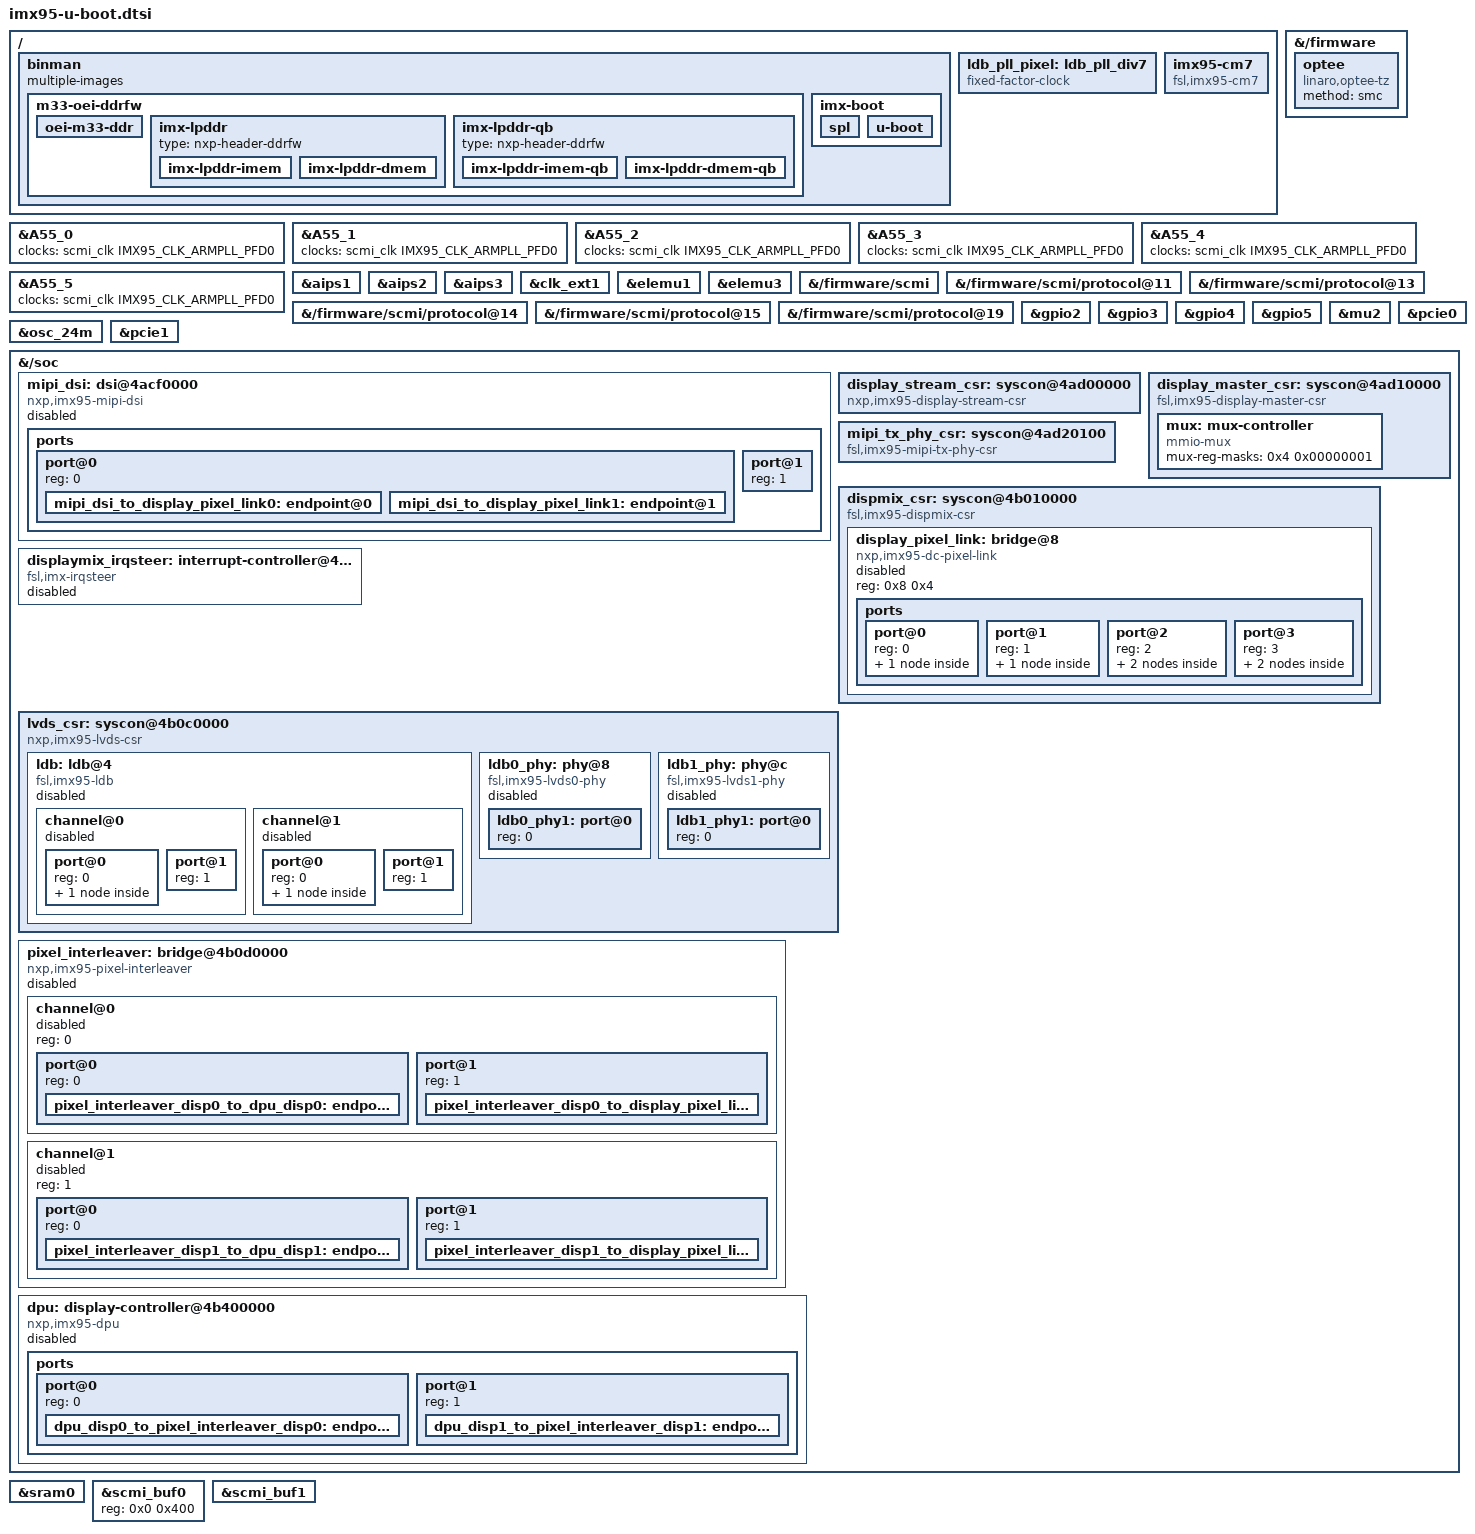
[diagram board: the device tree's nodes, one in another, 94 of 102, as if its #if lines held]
// SPDX-License-Identifier: GPL-2.0+
/*
 * Copyright 2025 NXP
 */

 #include <dt-bindings/clock/nxp,imx95-clock.h>

#ifdef CONFIG_OPTEE
&{/firmware} {
	optee {
		compatible = "linaro,optee-tz";
		method = "smc";
	};
};
#endif

/ {
	binman {
		multiple-images;

		m33-oei-ddrfw {
			pad-byte = <0x00>;
			align-size = <0x8>;
			filename = "m33-oei-ddrfw.bin";

			oei-m33-ddr {
				align-size = <0x4>;
				filename = "oei-m33-ddr.bin";
				type = "blob-ext";
			};

			imx-lpddr {
				type = "nxp-header-ddrfw";

				imx-lpddr-imem {
					filename = "lpddr5_imem_v202409.bin";
					type = "blob-ext";
				};

				imx-lpddr-dmem {
					filename = "lpddr5_dmem_v202409.bin";
					type = "blob-ext";
				};
			};

			imx-lpddr-qb {
				type = "nxp-header-ddrfw";

				imx-lpddr-imem-qb {
					filename = "lpddr5_imem_qb_v202409.bin";
					type = "blob-ext";
				};

				imx-lpddr-dmem-qb {
					filename = "lpddr5_dmem_qb_v202409.bin";
					type = "blob-ext";
				};
			};
		};

		imx-boot {
			filename = "flash.bin";
			pad-byte = <0x00>;

			spl {
				type = "nxp-imx9image";
				cfg-path = "spl/u-boot-spl.cfgout";
				args;

#ifndef CONFIG_IMX95_A0
				cntr-version = <2>;
#endif
				boot-from = "sd";
				soc-type = "IMX9";
#ifdef CONFIG_IMX95_A0
				append = "mx95a0-ahab-container.img";
#else
				append = "mx95b0-ahab-container.img";
#endif
				container;
#ifndef CONFIG_IMX95_A0
				dummy-ddr;
#endif
				image0 = "oei", "m33-oei-ddrfw.bin", "0x1ffc0000";
				hold = <0x10000>;
#ifdef CONFIG_IMX95_A0
				image1 = "oei", "oei-m33-tcm.bin", "0x1ffc0000";
#endif
				image2 = "m33", "m33_image.bin", "0x1ffc0000";
				image3 = "a55", "spl/u-boot-spl.bin", "0x20480000";
				dummy-v2x = <0x8b000000>;
			};

			u-boot {
				type = "nxp-imx9image";
				cfg-path = "u-boot-container.cfgout";
				args;

#ifndef CONFIG_IMX95_A0
				cntr-version = <2>;
#endif
				boot-from = "sd";
				soc-type = "IMX9";
				container;
				image0 = "a55", "bl31.bin", "0x8a200000";
				image1 = "a55", "u-boot.bin", "0x90200000";
			};
		};
	};

	ldb_pll_pixel: ldb_pll_div7 {
		#clock-cells = <0>;
		compatible = "fixed-factor-clock";
		clocks = <&scmi_clk IMX95_CLK_LDBPLL>;
		clock-div = <7>;
		clock-mult = <1>;
		clock-output-names = "ldb_pll_div7";
	};

	imx95-cm7 {
		compatible = "fsl,imx95-cm7";
	};
};

&A55_0 {
	clocks = <&scmi_clk IMX95_CLK_ARMPLL_PFD0>;
	/delete-property/ power-domains;
};

&A55_1 {
	clocks = <&scmi_clk IMX95_CLK_ARMPLL_PFD0>;
	/delete-property/ power-domains;
};

&A55_2 {
	clocks = <&scmi_clk IMX95_CLK_ARMPLL_PFD0>;
	/delete-property/ power-domains;
};

&A55_3 {
	clocks = <&scmi_clk IMX95_CLK_ARMPLL_PFD0>;
	/delete-property/ power-domains;
};

&A55_4 {
	clocks = <&scmi_clk IMX95_CLK_ARMPLL_PFD0>;
	/delete-property/ power-domains;
};

&A55_5 {
	clocks = <&scmi_clk IMX95_CLK_ARMPLL_PFD0>;
	/delete-property/ power-domains;
};

&aips1 {
	bootph-all;
};

&aips2 {
	bootph-all;
};

&aips3 {
	bootph-pre-ram;
};

&clk_ext1 {
	bootph-all;
};

&elemu1 {
	bootph-all;
	status = "okay";
};

&elemu3 {
	bootph-all;
	status = "okay";
};

&{/firmware} {
	bootph-all;
};

&{/firmware/scmi} {
	bootph-all;
};

&{/firmware/scmi/protocol@11} {
	bootph-all;
};

&{/firmware/scmi/protocol@13} {
	bootph-all;
};

&{/firmware/scmi/protocol@14} {
	bootph-all;
};

&{/firmware/scmi/protocol@15} {
	bootph-all;
};

&{/firmware/scmi/protocol@19} {
	bootph-all;
};

&gpio2 {
	bootph-pre-ram;
};

&gpio3 {
	bootph-pre-ram;
};

&gpio4 {
	bootph-pre-ram;
};

&gpio5 {
	bootph-pre-ram;
};

&mu2 {
	bootph-all;
};

&osc_24m {
	bootph-all;
};

&pcie0 {
	assigned-clocks =<&scmi_clk IMX95_CLK_HSIOPLL_VCO>,
					 <&scmi_clk IMX95_CLK_HSIOPLL>,
					 <&scmi_clk IMX95_CLK_HSIOPCIEAUX>;
	assigned-clock-parents = <0>, <&scmi_clk IMX95_CLK_HSIOPLL_VCO>,
				 <&scmi_clk IMX95_CLK_SYSPLL1_PFD1_DIV2>;
};

&pcie1 {
	assigned-clocks =<&scmi_clk IMX95_CLK_HSIOPLL_VCO>,
					 <&scmi_clk IMX95_CLK_HSIOPLL>,
					 <&scmi_clk IMX95_CLK_HSIOPCIEAUX>;
	assigned-clock-parents = <0>, <&scmi_clk IMX95_CLK_HSIOPLL_VCO>,
				 <&scmi_clk IMX95_CLK_SYSPLL1_PFD1_DIV2>;
};

&{/soc} {
	bootph-all;

	mipi_dsi: dsi@4acf0000 {
		compatible = "nxp,imx95-mipi-dsi";
		reg = <0x0 0x4acf0000 0x0 0x10000>;
		interrupt-parent = <&displaymix_irqsteer>;
		interrupts = <48>;
		clocks = <&scmi_clk IMX95_CLK_MIPIPHYCFG>,
			 <&scmi_clk IMX95_CLK_MIPIPHYPLLBYPASS>,
			 <&osc_24m>,
			 <&scmi_clk IMX95_CLK_CAMAPB>,
			 <&scmi_clk IMX95_CLK_DISP1PIX>;
		clock-names = "cfg", "bypass", "ref", "pclk", "pix";
		assigned-clocks = <&scmi_clk IMX95_CLK_MIPIPHYCFG>,
				  <&scmi_clk IMX95_CLK_MIPIPHYPLLBYPASS>;
		assigned-clock-parents = <&osc_24m>,
					 <&scmi_clk IMX95_CLK_VIDEOPLL1>;
		mux-controls = <&mux 0>;
		power-domains = <&scmi_devpd IMX95_PD_CAMERA>;
		nxp,disp-master-csr = <&display_master_csr>;
		nxp,disp-stream-csr = <&display_stream_csr>;
		nxp,mipi-combo-phy-csr = <&mipi_tx_phy_csr>;
		status = "disabled";

		ports {
			#address-cells = <1>;
			#size-cells = <0>;

			port@0 {
				#address-cells = <1>;
				#size-cells = <0>;
				reg = <0>;

				mipi_dsi_to_display_pixel_link0: endpoint@0 {
					reg = <0>;
					remote-endpoint = <&display_pixel_link0_to_mipi_dsi>;
				};

				mipi_dsi_to_display_pixel_link1: endpoint@1 {
					reg = <1>;
					remote-endpoint = <&display_pixel_link1_to_mipi_dsi>;
				};
			};

			port@1 {
				reg = <1>;
			};
		};
	};

	display_stream_csr: syscon@4ad00000 {
		compatible = "nxp,imx95-display-stream-csr", "syscon", "simple-mfd";
		reg = <0x0 0x4ad00000 0x0 0x10000>;
		clocks = <&scmi_clk IMX95_CLK_CAMAPB>;
	};

	display_master_csr: syscon@4ad10000 {
		compatible = "fsl,imx95-display-master-csr", "syscon";
		reg = <0x0 0x4ad10000 0x0 0x10000>;
		#clock-cells = <1>;
		clocks = <&scmi_clk IMX95_CLK_CAMAPB>;
		power-domains = <&scmi_devpd IMX95_PD_CAMERA>;

		mux: mux-controller {
			compatible = "mmio-mux";
			#mux-control-cells = <1>;
			mux-reg-masks = <0x4 0x00000001>; /* Pixel_link_sel */
		};
	};

	mipi_tx_phy_csr: syscon@4ad20100 {
		compatible = "fsl,imx95-mipi-tx-phy-csr", "syscon";
		reg = <0x0 0x4ad20100 0x0 0x14>;
		clocks = <&scmi_clk IMX95_CLK_CAMAPB>;
	};

	dispmix_csr: syscon@4b010000 {
		compatible = "fsl,imx95-dispmix-csr", "syscon";
		#address-cells = <1>;
		#size-cells = <1>;
		reg = <0x0 0x4b010000 0x0 0x10000>;
		#clock-cells = <1>;
		clocks = <&scmi_clk IMX95_CLK_DISPAPB>;
		power-domains = <&scmi_devpd IMX95_PD_DISPLAY>;
		assigned-clocks = <&scmi_clk IMX95_CLK_DISPAXI>,
				  <&scmi_clk IMX95_CLK_DISPOCRAM>,
				  <&scmi_clk IMX95_CLK_DISPAPB>;
		assigned-clock-parents = <&scmi_clk IMX95_CLK_SYSPLL1_PFD1>,
					 <&scmi_clk IMX95_CLK_SYSPLL1_PFD1>,
					 <&scmi_clk IMX95_CLK_SYSPLL1_PFD1_DIV2>;
		assigned-clock-rates = <400000000>, <400000000>, <133333333>;

		display_pixel_link: bridge@8 {
			compatible = "nxp,imx95-dc-pixel-link";
			reg = <0x8 0x4>;
			status = "disabled";

			ports {
				#address-cells = <1>;
				#size-cells = <0>;

				port@0 {
					reg = <0>;

					display_pixel_link0_to_pixel_interleaver_disp0: endpoint {
						remote-endpoint = <&pixel_interleaver_disp0_to_display_pixel_link0>;
					};
				};

				port@1 {
					reg = <1>;

					display_pixel_link1_to_pixel_interleaver_disp1: endpoint {
						remote-endpoint = <&pixel_interleaver_disp1_to_display_pixel_link1>;
					};
				};

				port@2 {
					#address-cells = <1>;
					#size-cells = <0>;
					reg = <2>;

					display_pixel_link0_to_mipi_dsi: endpoint@0 {
						reg = <0>;
						remote-endpoint = <&mipi_dsi_to_display_pixel_link0>;
					};

					display_pixel_link0_to_ldb_ch0: endpoint@1 {
						reg = <1>;
						remote-endpoint = <&ldb_ch0_to_display_pixel_link0>;
					};
				};

				port@3 {
					#address-cells = <1>;
					#size-cells = <0>;
					reg = <3>;

					display_pixel_link1_to_mipi_dsi: endpoint@0 {
						reg = <0>;
						remote-endpoint = <&mipi_dsi_to_display_pixel_link1>;
					};

					display_pixel_link1_to_ldb_ch1: endpoint@1 {
						reg = <1>;
						remote-endpoint = <&ldb_ch1_to_display_pixel_link1>;
					};
				};
			};
		};
	};

	displaymix_irqsteer: interrupt-controller@4b0b0000 {
		compatible = "fsl,imx-irqsteer";
		reg = <0x0 0x4b0b0000 0x0 0x1000>;
		interrupts = <GIC_SPI 214 IRQ_TYPE_LEVEL_HIGH>,
			     <GIC_SPI 215 IRQ_TYPE_LEVEL_HIGH>,
			     <GIC_SPI 216 IRQ_TYPE_LEVEL_HIGH>,
			     <GIC_SPI 217 IRQ_TYPE_LEVEL_HIGH>,
			     <GIC_SPI 218 IRQ_TYPE_LEVEL_HIGH>,
			     <GIC_SPI 303 IRQ_TYPE_LEVEL_HIGH>,	/* reserved */
			     <GIC_SPI 303 IRQ_TYPE_LEVEL_HIGH>,	/* reserved */
			     <GIC_SPI 219 IRQ_TYPE_LEVEL_HIGH>;
		power-domains = <&scmi_devpd IMX95_PD_DISPLAY>;
		clocks = <&scmi_clk IMX95_CLK_DISPAPB>;
		clock-names = "ipg";
		fsl,channel = <0>;
		fsl,num-irqs = <512>;
		interrupt-controller;
		#interrupt-cells = <1>;
		status = "disabled";
	};

	lvds_csr: syscon@4b0c0000 {
		compatible = "nxp,imx95-lvds-csr", "syscon";
		#address-cells = <1>;
		#size-cells = <1>;
		reg = <0x0 0x4b0c0000 0x0 0x10000>;
		#clock-cells = <1>;
		clocks = <&scmi_clk IMX95_CLK_DISPAPB>;
		power-domains = <&scmi_devpd IMX95_PD_DISPLAY>;

		ldb: ldb@4 {
			compatible = "fsl,imx95-ldb";
			#address-cells = <1>;
			#size-cells = <0>;
			reg = <0x4 0x4>;
			clocks = <&lvds_csr IMX95_CLK_DISPMIX_PIX_DI0_GATE>,
				 <&lvds_csr IMX95_CLK_DISPMIX_PIX_DI1_GATE>,
				 <&lvds_csr IMX95_CLK_DISPMIX_LVDS_CH0_GATE>,
				 <&lvds_csr IMX95_CLK_DISPMIX_LVDS_CH1_GATE>;
			clock-names = "ldb_di0", "ldb_di1", "ldb_ch0", "ldb_ch1";
			status = "disabled";

			channel@0 {
				#address-cells = <1>;
				#size-cells = <0>;
				reg = <0>;
				phys = <&ldb0_phy1>;
				phy-names = "lvds_phy";
				status = "disabled";

				port@0 {
					reg = <0>;

					ldb_ch0_to_display_pixel_link0: endpoint {
						remote-endpoint = <&display_pixel_link0_to_ldb_ch0>;
					};
				};

				port@1 {
					reg = <1>;
				};
			};

			channel@1 {
				#address-cells = <1>;
				#size-cells = <0>;
				reg = <1>;
				phys = <&ldb1_phy1>;
				phy-names = "lvds_phy";
				status = "disabled";

				port@0 {
					reg = <0>;

					ldb_ch1_to_display_pixel_link1: endpoint {
						remote-endpoint = <&display_pixel_link1_to_ldb_ch1>;
					};
				};

				port@1 {
					reg = <1>;
				};
			};
		};

		ldb0_phy: phy@8 {
			compatible = "fsl,imx95-lvds0-phy";
			#address-cells = <1>;
			#size-cells = <0>;
			reg = <0x8 0x4>;
			gpr = <&lvds_csr>;
			clocks = <&scmi_clk IMX95_CLK_DISPAPB>;
			clock-names = "apb";
			power-domains = <&scmi_devpd IMX95_PD_DISPLAY>;
			status = "disabled";

			ldb0_phy1: port@0 {
				reg = <0>;
				#phy-cells = <0>;
			};
		};

		ldb1_phy: phy@c {
			compatible = "fsl,imx95-lvds1-phy";
			#address-cells = <1>;
			#size-cells = <0>;
			reg = <0xc 0x4>;
			gpr = <&lvds_csr>;
			clocks = <&scmi_clk IMX95_CLK_DISPAPB>;
			clock-names = "apb";
			power-domains = <&scmi_devpd IMX95_PD_DISPLAY>;
			status = "disabled";

			ldb1_phy1: port@0 {
				reg = <0>;
				#phy-cells = <0>;
			};
		};
	};

	pixel_interleaver: bridge@4b0d0000 {
		compatible = "nxp,imx95-pixel-interleaver";
		#address-cells = <1>;
		#size-cells = <0>;
		reg = <0x0 0x4b0d0000 0x0 0x20000>;
		interrupt-parent = <&displaymix_irqsteer>;
		interrupts = <62>;
		clocks = <&scmi_clk IMX95_CLK_DISPAPB>;
		nxp,blk-ctrl = <&dispmix_csr>;
		status = "disabled";

		channel@0 {
			#address-cells = <1>;
			#size-cells = <0>;
			reg = <0>;
			status = "disabled";

			port@0 {
				reg = <0>;

				pixel_interleaver_disp0_to_dpu_disp0: endpoint {
					remote-endpoint = <&dpu_disp0_to_pixel_interleaver_disp0>;
				};
			};

			port@1 {
				reg = <1>;

				pixel_interleaver_disp0_to_display_pixel_link0: endpoint {
					remote-endpoint = <&display_pixel_link0_to_pixel_interleaver_disp0>;
				};
			};
		};

		channel@1 {
			#address-cells = <1>;
			#size-cells = <0>;
			reg = <1>;
			status = "disabled";

			port@0 {
				reg = <0>;

				pixel_interleaver_disp1_to_dpu_disp1: endpoint {
					remote-endpoint = <&dpu_disp1_to_pixel_interleaver_disp1>;
				};
			};

			port@1 {
				reg = <1>;

				pixel_interleaver_disp1_to_display_pixel_link1: endpoint {
					remote-endpoint = <&display_pixel_link1_to_pixel_interleaver_disp1>;
				};
			};
		};
	};

	dpu: display-controller@4b400000 {
		compatible = "nxp,imx95-dpu";
		reg = <0x0 0x4b400000 0x0 0x400000>;
		interrupt-parent = <&displaymix_irqsteer>;
		interrupts = <448>, <449>, <450>,  <64>,
			      <65>,  <66>,  <67>,  <68>,
			      <69>, <192>, <193>, <194>,
			     <195>, <196>, <197>,  <70>,
			      <71>,  <72>,  <73>,  <74>,
			      <75>,  <76>,  <77>,  <78>,
			      <79>,  <80>,  <81>,  <82>,
			      <83>,  <84>,  <85>,  <86>,
			      <87>,  <88>,  <89>,  <90>,
			      <91>,  <92>, <198>, <199>,
			     <200>, <201>, <202>, <203>,
			     <204>, <205>, <206>, <207>,
			     <208>, <209>, <210>, <211>,
			     <212>, <451>,   <1>,   <2>,
			       <3>,   <4>,  <93>,  <94>,
			      <95>,  <96>,  <97>,  <98>,
			      <99>, <100>, <101>, <102>,
			     <103>, <104>, <105>, <106>,
			     <213>, <214>, <215>, <216>,
			     <217>, <218>, <219>, <220>,
			     <221>, <222>, <223>, <224>,
			     <225>, <226>;
		interrupt-names = "store9_shdload",
				  "store9_framecomplete",
				  "store9_seqcomplete",
				  "extdst0_shdload",
				  "extdst0_framecomplete",
				  "extdst0_seqcomplete",
				  "extdst4_shdload",
				  "extdst4_framecomplete",
				  "extdst4_seqcomplete",
				  "extdst1_shdload",
				  "extdst1_framecomplete",
				  "extdst1_seqcomplete",
				  "extdst5_shdload",
				  "extdst5_framecomplete",
				  "extdst5_seqcomplete",
				  "domainblend0_shdload",
				  "domainblend0_framecomplete",
				  "domainblend0_seqcomplete",
				  "disengcfg_shdload0",
				  "disengcfg_framecomplete0",
				  "disengcfg_seqcomplete0",
				  "framegen0_int0",
				  "framegen0_int1",
				  "framegen0_int2",
				  "framegen0_int3",
				  "sig0_shdload",
				  "sig0_valid",
				  "sig0_error",
				  "sig0_cluster_error",
				  "sig0_cluster_match",
				  "sig2_shdload",
				  "sig2_valid",
				  "sig2_error",
				  "sig2_cluster_error",
				  "sig2_cluster_match",
				  "idhash0_shdload",
				  "idhash0_valid",
				  "idhash0_window_error",
				  "domainblend1_shdload",
				  "domainblend1_framecomplete",
				  "domainblend1_seqcomplete",
				  "disengcfg_shdload1",
				  "disengcfg_framecomplete1",
				  "disengcfg_seqcomplete1",
				  "framegen1_int0",
				  "framegen1_int1",
				  "framegen1_int2",
				  "framegen1_int3",
				  "sig1_shdload",
				  "sig1_valid",
				  "sig1_error",
				  "sig1_cluster_error",
				  "sig1_cluster_match",
				  "cmdseq_error",
				  "comctrl_sw0",
				  "comctrl_sw1",
				  "comctrl_sw2",
				  "comctrl_sw3",
				  "framegen0_primsync_on",
				  "framegen0_primsync_off",
				  "framegen0_overflow0_on",
				  "framegen0_overflow0_off",
				  "framegen0_underrun0_on",
				  "framegen0_underrun0_off",
				  "framegen0_threshold0_rise",
				  "framegen0_threshold0_fail",
				  "framegen0_overflow1_on",
				  "framegen0_overflow1_off",
				  "framegen0_underrun1_on",
				  "framegen0_underrun1_off",
				  "framegen0_threshold1_rise",
				  "framegen0_threshold1_fail",
				  "framegen1_primsync_on",
				  "framegen1_primsync_off",
				  "framegen1_overflow0_on",
				  "framegen1_overflow0_off",
				  "framegen1_underrun0_on",
				  "framegen1_underrun0_off",
				  "framegen1_threshold0_rise",
				  "framegen1_threshold0_fail",
				  "framegen1_overflow1_on",
				  "framegen1_overflow1_off",
				  "framegen1_underrun1_on",
				  "framegen1_underrun1_off",
				  "framegen1_threshold1_rise",
				  "framegen1_threshold1_fail";
		clocks = <&scmi_clk IMX95_CLK_DISP1PIX>,
			 <&scmi_clk IMX95_CLK_DISPAPB>,
			 <&scmi_clk IMX95_CLK_DISPAXI>,
			 <&scmi_clk IMX95_CLK_DISPOCRAM>,
			 <&ldb_pll_pixel>,
			 <&scmi_clk IMX95_CLK_LDBPLL_VCO>;
		clock-names = "pix", "apb", "axi", "ocram", "ldb", "ldb_vco";
		power-domains = <&scmi_devpd IMX95_PD_DISPLAY>;
		nxp,blk-ctrl = <&dispmix_csr>;
		status = "disabled";

		ports {
			#address-cells = <1>;
			#size-cells = <0>;

			port@0 {
				reg = <0>;

				dpu_disp0_to_pixel_interleaver_disp0: endpoint {
					remote-endpoint = <&pixel_interleaver_disp0_to_dpu_disp0>;
				};
			};

			port@1 {
				reg = <1>;

				dpu_disp1_to_pixel_interleaver_disp1: endpoint {
					remote-endpoint = <&pixel_interleaver_disp1_to_dpu_disp1>;
				};
			};
		};
	};
};

&sram0 {
	bootph-all;
};

&scmi_buf0 {
	reg = <0x0 0x400>;
	bootph-all;
};

&scmi_buf1 {
	bootph-all;
};
